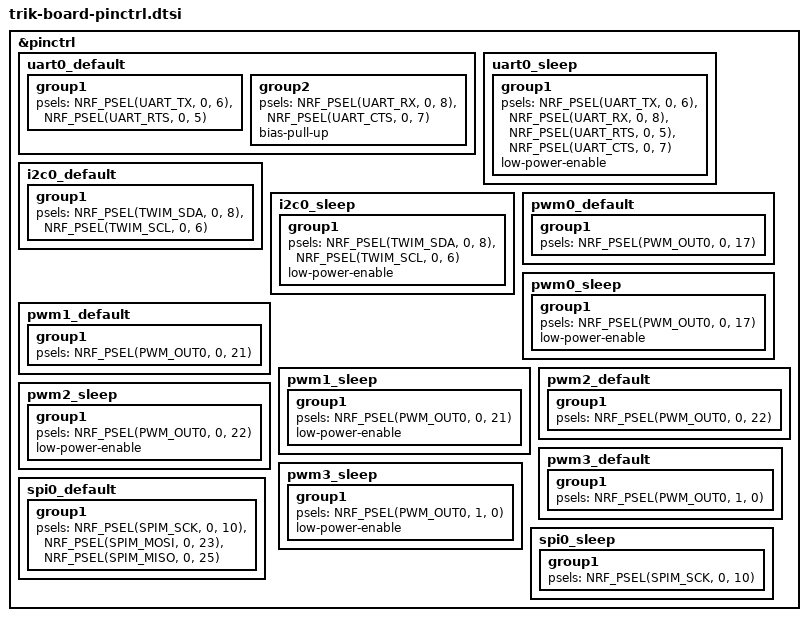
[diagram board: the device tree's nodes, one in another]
&pinctrl {
	uart0_default: uart0_default {
		group1 {
			psels = <NRF_PSEL(UART_TX, 0, 6)>,
				<NRF_PSEL(UART_RTS, 0, 5)>;
		};

		group2 {
			psels = <NRF_PSEL(UART_RX, 0, 8)>,
				<NRF_PSEL(UART_CTS, 0, 7)>;
			bias-pull-up;
		};
	};

	uart0_sleep: uart0_sleep {
		group1 {
			psels = <NRF_PSEL(UART_TX, 0, 6)>,
				<NRF_PSEL(UART_RX, 0, 8)>,
				<NRF_PSEL(UART_RTS, 0, 5)>,
				<NRF_PSEL(UART_CTS, 0, 7)>;
			low-power-enable;
		};
	};

	i2c0_default: i2c0_default {
		group1 {
			psels = <NRF_PSEL(TWIM_SDA, 0, 8)>,
				<NRF_PSEL(TWIM_SCL, 0, 6)>;
		};
	};

	i2c0_sleep: i2c0_sleep {
		group1 {
			psels = <NRF_PSEL(TWIM_SDA, 0, 8)>,
				<NRF_PSEL(TWIM_SCL, 0, 6)>;
			low-power-enable;
		};
	};

	pwm0_default: pwm0_default {
		group1 { psels = <NRF_PSEL(PWM_OUT0, 0, 17)>; };
	};

	pwm0_sleep: pwm0_sleep {
		group1 {
			psels = <NRF_PSEL(PWM_OUT0, 0, 17)>;
			low-power-enable;
		};
	};

	pwm1_default: pwm1_default {
		group1 { psels = <NRF_PSEL(PWM_OUT0, 0, 21)>; };
	};

	pwm1_sleep: pwm1_sleep {
		group1 {
			psels = <NRF_PSEL(PWM_OUT0, 0, 21)>;
			low-power-enable;
		};
	};

	pwm2_default: pwm2_default {
		group1 { psels = <NRF_PSEL(PWM_OUT0, 0, 22)>; };
	};

	pwm2_sleep: pwm2_sleep {
		group1 {
			psels = <NRF_PSEL(PWM_OUT0, 0, 22)>;
			low-power-enable;
		};
	};

	pwm3_default: pwm3_default {
		group1 { psels = <NRF_PSEL(PWM_OUT0, 1, 0)>; };
	};

	pwm3_sleep: pwm3_sleep {
		group1 {
			psels = <NRF_PSEL(PWM_OUT0, 1, 0)>;
			low-power-enable;
		};
	};

	spi0_default: spi0_default {
		group1 {
			psels = <NRF_PSEL(SPIM_SCK, 0, 10)>,
					<NRF_PSEL(SPIM_MOSI, 0, 23)>,
					<NRF_PSEL(SPIM_MISO, 0, 25)>;
		};
	};

	spi0_sleep: spi0_sleep {
		group1 {
			psels = <NRF_PSEL(SPIM_SCK, 0, 10)>;
		};
	};
};
